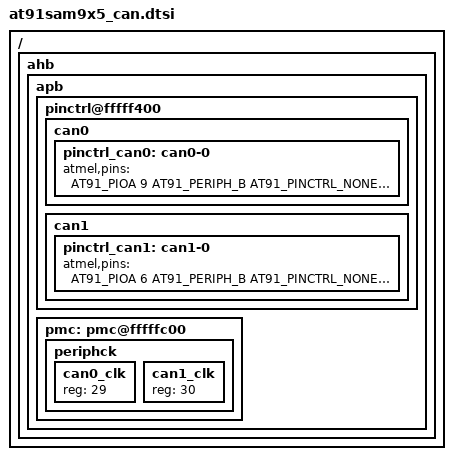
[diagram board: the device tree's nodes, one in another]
/*
 * at91sam9x5_macb0.dtsi - Device Tree Include file for AT91SAM9x5 SoC with 1
 * Ethernet interface.
 *
 * Copyright (C) 2013 Boris BREZILLON <b.brezillon@overkiz.com>
 *
 * Licensed under GPLv2.
 */

#include <dt-bindings/pinctrl/at91.h>
#include <dt-bindings/interrupt-controller/irq.h>

/ {
	ahb {
		apb {
			pinctrl@fffff400 {
				can0 {
					pinctrl_can0: can0-0 {
						atmel,pins =
							<AT91_PIOA 9 AT91_PERIPH_B AT91_PINCTRL_NONE	/* PA9 periph B CANRX */
							 AT91_PIOA 10 AT91_PERIPH_B AT91_PINCTRL_NONE>;	/* PA10 periph B CANTX */
					};
				};

				can1 {
					pinctrl_can1: can1-0 {
						atmel,pins =
							<AT91_PIOA 6 AT91_PERIPH_B AT91_PINCTRL_NONE	/* PA6 periph B CANRX */
							 AT91_PIOA 5 AT91_PERIPH_B AT91_PINCTRL_NONE>;	/* PA5 periph B CANTX */
					};
				};
			};

			pmc: pmc@fffffc00 {
				periphck {
					can0_clk: can0_clk {
						#clock-cells = <0>;
						reg = <29>;
					};

                                        can1_clk: can1_clk {
                                                #clock-cells = <0>;
                                                reg = <30>;
                                        };
				};
			};
		};
	};
};
